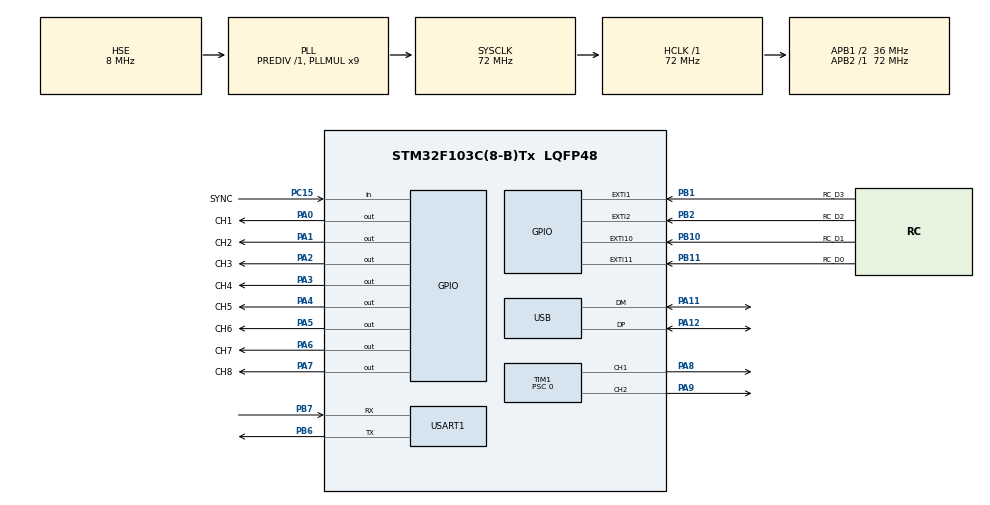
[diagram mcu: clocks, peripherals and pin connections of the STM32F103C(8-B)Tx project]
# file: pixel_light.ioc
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Mcu.Family=STM32F1
Mcu.Name=STM32F103C(8-B)Tx
Mcu.Package=LQFP48
NVIC.EXTI15_10_IRQn=true\:3\:0\:false\:false\:true\:true\:true\:true
NVIC.EXTI1_IRQn=true\:3\:0\:false\:false\:true\:true\:true\:true
NVIC.EXTI2_IRQn=true\:3\:0\:false\:false\:true\:true\:true\:true
NVIC.PriorityGroup=NVIC_PRIORITYGROUP_4
NVIC.USB_LP_CAN1_RX0_IRQn=true\:0\:0\:false\:false\:true\:false\:true\:true
PA0-WKUP.GPIO_Label=CH1
PA0-WKUP.GPIO_Speed=GPIO_SPEED_FREQ_HIGH
PA0-WKUP.Signal=GPIO_Output
PA1.GPIO_Label=CH2
PA1.GPIO_Speed=GPIO_SPEED_FREQ_HIGH
PA1.Signal=GPIO_Output
PA11.Mode=Device
PA11.Signal=USB_DM
PA12.Mode=Device
PA12.Signal=USB_DP
PA13.Mode=Serial_Wire
PA13.Signal=SYS_JTMS-SWDIO
PA14.Mode=Serial_Wire
PA14.Signal=SYS_JTCK-SWCLK
PA2.GPIO_Label=CH3
PA2.GPIO_Speed=GPIO_SPEED_FREQ_HIGH
PA2.Signal=GPIO_Output
PA3.GPIO_Label=CH4
PA3.GPIO_Speed=GPIO_SPEED_FREQ_HIGH
PA3.Signal=GPIO_Output
PA4.GPIO_Label=CH5
PA4.GPIO_Speed=GPIO_SPEED_FREQ_HIGH
PA4.Signal=GPIO_Output
PA5.GPIO_Label=CH6
PA5.GPIO_Speed=GPIO_SPEED_FREQ_HIGH
PA5.Signal=GPIO_Output
PA6.GPIO_Label=CH7
PA6.GPIO_Speed=GPIO_SPEED_FREQ_HIGH
PA6.Signal=GPIO_Output
PA7.GPIO_Label=CH8
PA7.GPIO_Speed=GPIO_SPEED_FREQ_HIGH
PA7.Signal=GPIO_Output
PA8.Signal=S_TIM1_CH1
PA9.Signal=S_TIM1_CH2
PB1.GPIO_Label=RC_D3
PB1.GPIO_ModeDefaultEXTI=GPIO_MODE_IT_RISING_FALLING
PB1.GPIO_PuPd=GPIO_PULLDOWN
PB1.Signal=GPXTI1
PB10.GPIO_Label=RC_D1
PB10.GPIO_ModeDefaultEXTI=GPIO_MODE_IT_RISING_FALLING
PB10.GPIO_PuPd=GPIO_PULLDOWN
PB10.Signal=GPXTI10
PB11.GPIO_Label=RC_D0
PB11.GPIO_ModeDefaultEXTI=GPIO_MODE_IT_RISING_FALLING
PB11.GPIO_PuPd=GPIO_PULLDOWN
PB11.Signal=GPXTI11
PB2.GPIO_Label=RC_D2
PB2.GPIO_ModeDefaultEXTI=GPIO_MODE_IT_RISING_FALLING
PB2.GPIO_PuPd=GPIO_PULLDOWN
PB2.Signal=GPXTI2
PB6.Mode=Asynchronous
PB6.Signal=USART1_TX
PB7.Mode=Asynchronous
PB7.Signal=USART1_RX
PC15-OSC32_OUT.GPIO_Label=SYNC
PC15-OSC32_OUT.Signal=GPIO_Input
PD0-OSC_IN.Mode=HSE-External-Oscillator
PD0-OSC_IN.Signal=RCC_OSC_IN
PD1-OSC_OUT.Mode=HSE-External-Oscillator
PD1-OSC_OUT.Signal=RCC_OSC_OUT
ProjectManager.HeapSize=0x200
ProjectManager.StackSize=0x400
ProjectManager.TargetToolchain=MDK-ARM V5.32
RCC.AHBFreq_Value=72000000
RCC.APB1CLKDivider=RCC_HCLK_DIV2
RCC.APB1Freq_Value=36000000
RCC.APB1TimFreq_Value=72000000
RCC.APB2Freq_Value=72000000
RCC.APB2TimFreq_Value=72000000
RCC.HCLKFreq_Value=72000000
RCC.PLLMUL=RCC_PLL_MUL9
RCC.SYSCLKFreq_VALUE=72000000
RCC.SYSCLKSource=RCC_SYSCLKSOURCE_PLLCLK
RCC.USBFreq_Value=48000000
RCC.USBPrescaler=RCC_USBCLKSOURCE_PLL_DIV1_5
SH.S_TIM1_CH1.0=TIM1_CH1,PWM Generation1 CH1
SH.S_TIM1_CH2.0=TIM1_CH2,PWM Generation2 CH2
TIM1.Channel-PWM\ Generation1\ CH1=TIM_CHANNEL_1
TIM1.Channel-PWM\ Generation2\ CH2=TIM_CHANNEL_2
TIM1.Period=3599
TIM1.Prescaler=0
USART1.VirtualMode=VM_ASYNC
USB_DEVICE.APP_RX_DATA_SIZE=256
USB_DEVICE.APP_TX_DATA_SIZE=128
USB_DEVICE.CLASS_NAME_FS=CDC
USB_DEVICE.VirtualMode=Cdc
USB_DEVICE.VirtualModeFS=Cdc_FS
VP_TIM4_VS_ClockSourceINT.Mode=Internal
VP_USB_DEVICE_VS_USB_DEVICE_CDC_FS.Mode=CDC_FS
board=custom

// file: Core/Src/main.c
/* USER CODE BEGIN Header */
/**
  ******************************************************************************
  * @file           : main.c
  * @brief          : Main program body
  ******************************************************************************
  * @attention
  *
  * Copyright (c) 2026 STMicroelectronics.
  * All rights reserved.
  *
  * This software is licensed under terms that can be found in the LICENSE file
  * in the root directory of this software component.
  * If no LICENSE file comes with this software, it is provided AS-IS.
  *
  ******************************************************************************
  */
/* USER CODE END Header */
#include "main.h"
#include "tim.h"
#include "usart.h"
#include "usb_device.h"
#include "gpio.h"

/* USER CODE BEGIN Includes */
#include "app_config.h"
#include "app_controller.h"

/* USER CODE END Includes */

void SystemClock_Config(void);

int main(void)
{

  /* MCU Configuration--------------------------------------------------------*/

  /* Reset of all peripherals, Initializes the Flash interface and the Systick. */
  HAL_Init();

  /* Configure the system clock */
  SystemClock_Config();

  /* Initialize all configured peripherals */
  MX_GPIO_Init();
  MX_TIM1_Init();
  MX_TIM4_Init();
  MX_USART1_UART_Init();
  MX_USB_DEVICE_Init();
  /* USER CODE BEGIN 2 */
#if !APP_USB_ONLY_BRINGUP
  /* Initialize application drivers after CubeMX peripheral setup. */
  AppController_Init();
#endif

  /* USER CODE END 2 */

  /* Infinite loop */
  while (1)
  {

    /* USER CODE BEGIN 3 */
#if APP_USB_ONLY_BRINGUP
    HAL_Delay(1);
#else
    AppController_Poll(HAL_GetTick());
    HAL_Delay(1);
#endif
  }
  /* USER CODE END 3 */
}

void SystemClock_Config(void)
{
  RCC_OscInitTypeDef RCC_OscInitStruct = {0};
  RCC_ClkInitTypeDef RCC_ClkInitStruct = {0};
  RCC_PeriphCLKInitTypeDef PeriphClkInit = {0};

  /** Initializes the RCC Oscillators according to the specified parameters
  * in the RCC_OscInitTypeDef structure.
  */
  RCC_OscInitStruct.OscillatorType = RCC_OSCILLATORTYPE_HSE;
  RCC_OscInitStruct.HSEState = RCC_HSE_ON;
  RCC_OscInitStruct.HSEPredivValue = RCC_HSE_PREDIV_DIV1;
  RCC_OscInitStruct.HSIState = RCC_HSI_ON;
  RCC_OscInitStruct.PLL.PLLState = RCC_PLL_ON;
  RCC_OscInitStruct.PLL.PLLSource = RCC_PLLSOURCE_HSE;
  RCC_OscInitStruct.PLL.PLLMUL = RCC_PLL_MUL9;
  if (HAL_RCC_OscConfig(&RCC_OscInitStruct) != HAL_OK)
  {
    Error_Handler();
  }

  /** Initializes the CPU, AHB and APB buses clocks
  */
  RCC_ClkInitStruct.ClockType = RCC_CLOCKTYPE_HCLK|RCC_CLOCKTYPE_SYSCLK
                              |RCC_CLOCKTYPE_PCLK1|RCC_CLOCKTYPE_PCLK2;
  RCC_ClkInitStruct.SYSCLKSource = RCC_SYSCLKSOURCE_PLLCLK;
  RCC_ClkInitStruct.AHBCLKDivider = RCC_SYSCLK_DIV1;
  RCC_ClkInitStruct.APB1CLKDivider = RCC_HCLK_DIV2;
  RCC_ClkInitStruct.APB2CLKDivider = RCC_HCLK_DIV1;

  if (HAL_RCC_ClockConfig(&RCC_ClkInitStruct, FLASH_LATENCY_2) != HAL_OK)
  {
    Error_Handler();
  }
  PeriphClkInit.PeriphClockSelection = RCC_PERIPHCLK_USB;
  PeriphClkInit.UsbClockSelection = RCC_USBCLKSOURCE_PLL_DIV1_5;
  if (HAL_RCCEx_PeriphCLKConfig(&PeriphClkInit) != HAL_OK)
  {
    Error_Handler();
  }
}

void Error_Handler(void)
{
  __disable_irq();
  while (1)
  {
  }
}
